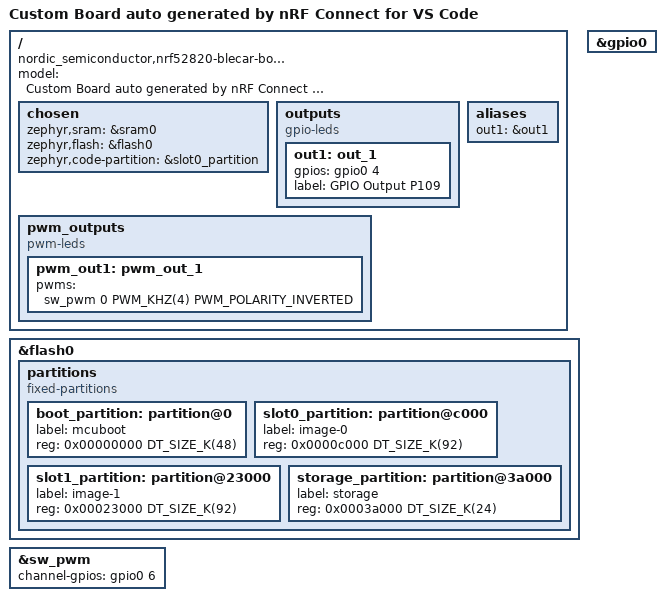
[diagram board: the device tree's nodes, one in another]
/dts-v1/;
#include <nordic/nrf52820_qdaa.dtsi>
#include "nrf52820_blecar_board-pinctrl.dtsi"

/ {
	model = "Custom Board auto generated by nRF Connect for VS Code";
	compatible = "nordic_semiconductor,nrf52820-blecar-board";

	chosen {
		zephyr,sram = &sram0;
		zephyr,flash = &flash0;
		zephyr,code-partition = &slot0_partition;
	};

	outputs {
		compatible = "gpio-leds";
		out1: out_1 {
			gpios = <&gpio0 4 GPIO_ACTIVE_HIGH>;
			label = "GPIO Output P109";
		};

	};

	pwm_outputs {
		compatible = "pwm-leds";
		pwm_out1: pwm_out_1 {
			pwms = <&sw_pwm 0 PWM_KHZ(4) PWM_POLARITY_INVERTED>;
		};
	};

	aliases {
		out1 = &out1;
		
	};

};

&flash0 {
	partitions {
		compatible = "fixed-partitions";
		#address-cells = <1>;
		#size-cells = <1>;

		boot_partition: partition@0 {
			label = "mcuboot";
			reg = <0x00000000 DT_SIZE_K(48)>;
		};

		slot0_partition: partition@c000 {
			label = "image-0";
			reg = <0x0000c000 DT_SIZE_K(92)>;
		};

		slot1_partition: partition@23000 {
			label = "image-1";
			reg = <0x00023000 DT_SIZE_K(92)>;
		};

		storage_partition: partition@3a000 {
			label = "storage";
			reg = <0x0003a000 DT_SIZE_K(24)>;
		};
	};
};

&gpio0
{
	status = "okay";
};

&sw_pwm {
	status = "okay";
	channel-gpios = <&gpio0 6 GPIO_ACTIVE_HIGH>;
};
